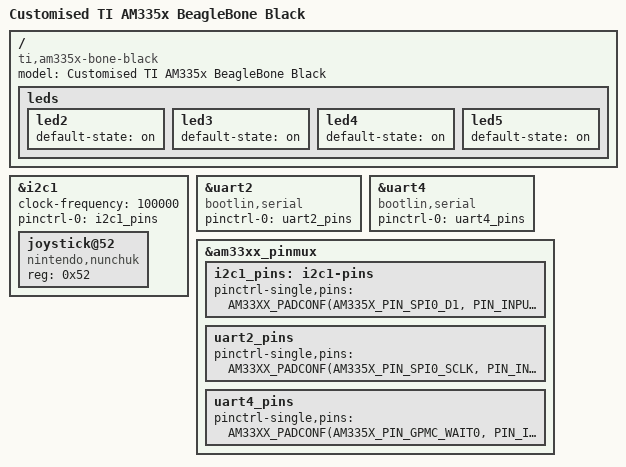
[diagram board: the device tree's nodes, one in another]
// SPDX-License-Identifier: GPL-2.0-only
/*
 * Copyright (C) 2012 Texas Instruments Incorporated - https://www.ti.com/
 */
/dts-v1/;

#include "am335x-boneblack.dts"

/ {
	model = "Customised TI AM335x BeagleBone Black";
	compatible = "ti,am335x-bone-black", "ti,am335x-bone", "ti,am33xx";

	leds {
		led2 {
			default-state = "on";
		};
		led3 {
			default-state = "on";
		};
		led4 {
			default-state = "on";
		};
		led5 {
			default-state = "on";
		};
	};
};


&i2c1 {
	status = "okay";
	clock-frequency = <100000>;
	pinctrl-names = "default";
	pinctrl-0 = <&i2c1_pins>;

	joystick@52 {
		compatible = "nintendo,nunchuk";
		reg = <0x52>;
	};
};

&uart2 {
	status = "okay";
	compatible = "bootlin,serial";
	pinctrl-0 = <&uart2_pins>;
	pinctrl-names = "default";
};

&uart4 {
	status = "okay";
	compatible = "bootlin,serial";
	pinctrl-0 = <&uart4_pins>;
	pinctrl-names = "default";
};

&am33xx_pinmux {
	i2c1_pins: i2c1-pins {
		pinctrl-single,pins = <
			/* spi0_d1.i2c1_sda */
			AM33XX_PADCONF(AM335X_PIN_SPI0_D1, PIN_INPUT_PULLUP, MUX_MODE2)
			/* spi0_cs0.i2c1_sc1 */
			AM33XX_PADCONF(AM335X_PIN_SPI0_CS0, PIN_INPUT_PULLUP, MUX_MODE2)
		>;
	};
	uart2_pins: uart2_pins {
		pinctrl-single,pins = <
			/* (A17) spi0_sclk.uart2_rxd */
			AM33XX_PADCONF(AM335X_PIN_SPI0_SCLK, PIN_INPUT_PULLUP, MUX_MODE1)
			/* (B17) spi0_d0.uart2_txd */
			AM33XX_PADCONF(AM335X_PIN_SPI0_D0, PIN_OUTPUT, MUX_MODE1)
		>;
	};
	uart4_pins: uart4_pins {
		pinctrl-single,pins = <
			/* (T17) gpmc_wait0.uart4_rxd */
			AM33XX_PADCONF(AM335X_PIN_GPMC_WAIT0, PIN_INPUT_PULLUP, MUX_MODE6)
			/* (U17) gpmc_wpn.uart4_txd */
			AM33XX_PADCONF(AM335X_PIN_GPMC_WPN, PIN_OUTPUT, MUX_MODE6)
		>;
	};
};
